AUTOSAR XML (schema 4-3-1)
package /TPC_Composition/Components
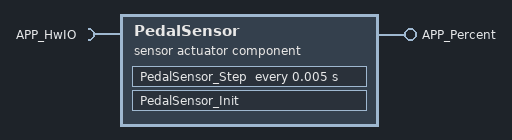
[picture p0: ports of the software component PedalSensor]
  sensor actuator sw component type PedalSensor
    require port APP_HwIO: nonqueued-receiver-com-spec{data-element=Value, init-value=0}, required-interface=APP_HwIO
    provide port APP_Percent: nonqueued-sender-com-spec{data-element=Value, init-value=0}, provided-interface=APP_Percent
    behavior PedalSensor_IB: data-type-mapping=PedalSensorDataTypeMappingsSet, handle-termination-and-restart=NO-SUPPORT
      timing event Event_PedalSensor_Step: start-on-event=PedalSensor_Step, period=0.005
      runnable PedalSensor_Init
      runnable PedalSensor_Step
        data-read-access:
          access IN_APP_HwIO_Value: accessed-variable=APP_HwIO.Value
        data-write-access:
          access OUT_APP_Percent_Value: accessed-variable=APP_Percent.Value
        parameter access SCALPRM_SetpointPercent_LkupTbl: accessed-parameter=SetpointPercent_LkupTbl, sw-calprm-axis-set={sw-axis-index=1, sw-axis-individual=sw-variable=APP_HwIO.Value}
      shared-parameters:
        parameter data prototype SetpointPercent_LkupTbl: category=CURVE, sw-calibration-access=READ-WRITE, type=Appl_SetpointPercent_LkupTbl, init-value=constant-reference={short-label=SetpointPercent_LkupTbl, constant=SetpointPercent_LkupTbl}
